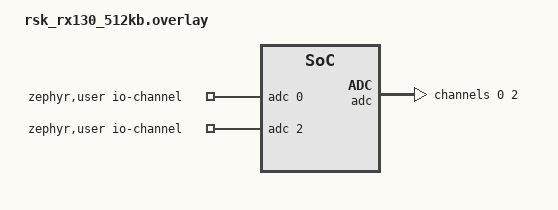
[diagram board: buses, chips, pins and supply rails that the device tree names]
/*
 * Copyright (c) 2025 Renesas Electronics Corporation
 *
 * SPDX-License-Identifier: Apache-2.0
 */

/ {
	zephyr,user {
		io-channels = <&adc 0>, <&adc 2>;
	};
};

&adc {
	#address-cells = <1>;
	#size-cells = <0>;

	channel@0 {
		reg = <0>;
		zephyr,gain = "ADC_GAIN_1";
		zephyr,reference = "ADC_REF_INTERNAL";
		zephyr,resolution = <12>;
		zephyr,acquisition-time = <ADC_ACQ_TIME_DEFAULT>;
		zephyr,vref-mv = <3300>;
	};

	channel@2 {
		reg = <2>;
		zephyr,gain = "ADC_GAIN_1";
		zephyr,reference = "ADC_REF_INTERNAL";
		zephyr,resolution = <12>;
		zephyr,acquisition-time = <ADC_ACQ_TIME_DEFAULT>;
		zephyr,vref-mv = <3300>;
	};
};
